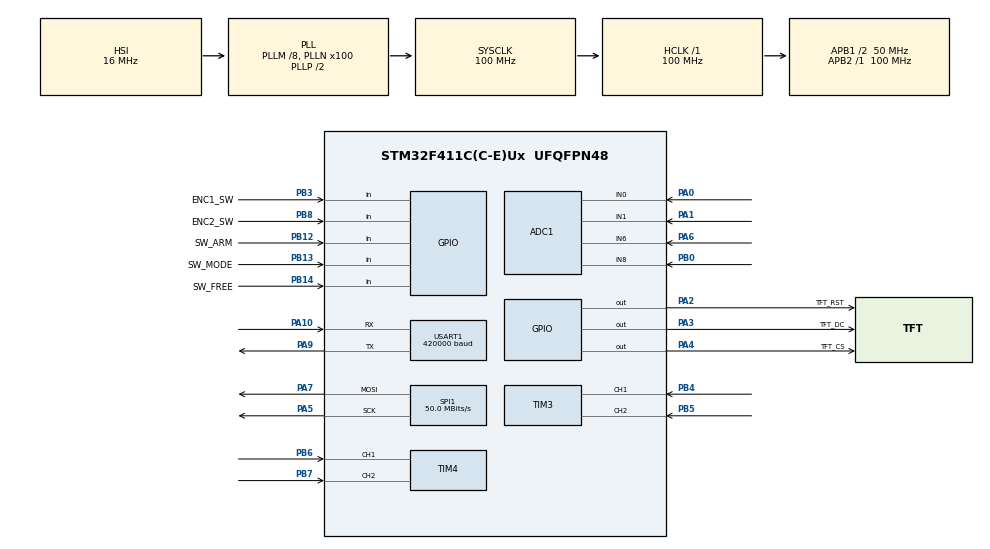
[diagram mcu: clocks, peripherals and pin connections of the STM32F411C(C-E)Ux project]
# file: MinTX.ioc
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ADC1.Channel-0\#ChannelRegularConversion=ADC_CHANNEL_0
ADC1.Channel-1\#ChannelRegularConversion=ADC_CHANNEL_1
ADC1.Channel-2\#ChannelRegularConversion=ADC_CHANNEL_6
ADC1.Channel-3\#ChannelRegularConversion=ADC_CHANNEL_8
ADC1.ContinuousConvMode=ENABLE
ADC1.DMAContinuousRequests=ENABLE
ADC1.EOCSelection=ADC_EOC_SEQ_CONV
ADC1.NbrOfConversion=4
ADC1.NbrOfConversionFlag=1
ADC1.Rank-0\#ChannelRegularConversion=1
ADC1.Rank-1\#ChannelRegularConversion=2
ADC1.Rank-2\#ChannelRegularConversion=3
ADC1.Rank-3\#ChannelRegularConversion=4
ADC1.SamplingTime-0\#ChannelRegularConversion=ADC_SAMPLETIME_84CYCLES
ADC1.SamplingTime-1\#ChannelRegularConversion=ADC_SAMPLETIME_84CYCLES
ADC1.SamplingTime-2\#ChannelRegularConversion=ADC_SAMPLETIME_84CYCLES
ADC1.SamplingTime-3\#ChannelRegularConversion=ADC_SAMPLETIME_84CYCLES
ADC1.ScanConvMode=ENABLE
ADC1.master=1
Dma.ADC1.0.Direction=DMA_PERIPH_TO_MEMORY
Dma.ADC1.0.FIFOMode=DMA_FIFOMODE_DISABLE
Dma.ADC1.0.Instance=DMA2_Stream0
Dma.ADC1.0.MemDataAlignment=DMA_MDATAALIGN_HALFWORD
Dma.ADC1.0.MemInc=DMA_MINC_ENABLE
Dma.ADC1.0.Mode=DMA_CIRCULAR
Dma.ADC1.0.PeriphDataAlignment=DMA_PDATAALIGN_HALFWORD
Dma.ADC1.0.PeriphInc=DMA_PINC_DISABLE
Dma.ADC1.0.Priority=DMA_PRIORITY_LOW
Dma.Request0=ADC1
Dma.Request1=SPI1_TX
Dma.SPI1_TX.1.Direction=DMA_MEMORY_TO_PERIPH
Dma.SPI1_TX.1.FIFOMode=DMA_FIFOMODE_DISABLE
Dma.SPI1_TX.1.Instance=DMA2_Stream2
Dma.SPI1_TX.1.MemDataAlignment=DMA_MDATAALIGN_BYTE
Dma.SPI1_TX.1.MemInc=DMA_MINC_ENABLE
Dma.SPI1_TX.1.Mode=DMA_NORMAL
Dma.SPI1_TX.1.PeriphDataAlignment=DMA_PDATAALIGN_BYTE
Dma.SPI1_TX.1.PeriphInc=DMA_PINC_DISABLE
Dma.SPI1_TX.1.Priority=DMA_PRIORITY_LOW
FREERTOS.Queues01=rcDataQueue,4,uint16_t,0,Dynamic,NULL,NULL
FREERTOS.Tasks01=DisplayTask,24,512,StartDisplayTask,Default,NULL,Dynamic,NULL,NULL;InputTask,40,256,StartInputTask,Default,NULL,Dynamic,NULL,NULL;CrsfTask,48,256,StartCrsfTask,Default,NULL,Dynamic,NULL,NULL;TelemetryTask,8,128,StartMonitorTask,Default,NULL,Dynamic,NULL,NULL
FREERTOS.configTOTAL_HEAP_SIZE=20480
Mcu.Family=STM32F4
Mcu.Name=STM32F411C(C-E)Ux
Mcu.Package=UFQFPN48
NVIC.DMA2_Stream0_IRQn=true\:5\:0\:false\:false\:true\:true\:false\:true\:true
NVIC.DMA2_Stream2_IRQn=true\:5\:0\:false\:false\:true\:true\:false\:true\:true
NVIC.PriorityGroup=NVIC_PRIORITYGROUP_4
NVIC.TIM1_TRG_COM_TIM11_IRQn=true\:15\:0\:false\:false\:true\:false\:false\:true\:true
NVIC.TimeBase=TIM1_TRG_COM_TIM11_IRQn
NVIC.TimeBaseIP=TIM11
NVIC.USART1_IRQn=true\:5\:0\:false\:false\:true\:true\:true\:true\:true
PA0-WKUP.Signal=ADCx_IN0
PA1.Signal=ADCx_IN1
PA10.Mode=Asynchronous
PA10.Signal=USART1_RX
PA13.Mode=Serial_Wire
PA13.Signal=SYS_JTMS-SWDIO
PA14.Mode=Serial_Wire
PA14.Signal=SYS_JTCK-SWCLK
PA2.GPIO_Label=TFT_RST
PA2.GPIO_Speed=GPIO_SPEED_FREQ_HIGH
PA2.PinState=GPIO_PIN_SET
PA2.Signal=GPIO_Output
PA3.GPIO_Label=TFT_DC
PA3.GPIO_Speed=GPIO_SPEED_FREQ_HIGH
PA3.PinState=GPIO_PIN_SET
PA3.Signal=GPIO_Output
PA4.GPIO_Label=TFT_CS
PA4.GPIO_Speed=GPIO_SPEED_FREQ_HIGH
PA4.PinState=GPIO_PIN_SET
PA4.Signal=GPIO_Output
PA5.Mode=TX_Only_Simplex_Unidirect_Master
PA5.Signal=SPI1_SCK
PA6.Signal=ADCx_IN6
PA7.Mode=TX_Only_Simplex_Unidirect_Master
PA7.Signal=SPI1_MOSI
PA9.Mode=Asynchronous
PA9.Signal=USART1_TX
PB0.Signal=ADCx_IN8
PB12.GPIO_Label=SW_ARM
PB12.GPIO_PuPd=GPIO_PULLUP
PB12.Signal=GPIO_Input
PB13.GPIO_Label=SW_MODE
PB13.GPIO_PuPd=GPIO_PULLUP
PB13.Signal=GPIO_Input
PB14.GPIO_Label=SW_FREE
PB14.GPIO_PuPd=GPIO_PULLUP
PB14.Signal=GPIO_Input
PB3.GPIO_Label=ENC1_SW
PB3.GPIO_PuPd=GPIO_PULLUP
PB3.Signal=GPIO_Input
PB4.GPIO_PuPd=GPIO_PULLUP
PB4.Signal=S_TIM3_CH1
PB5.GPIO_PuPd=GPIO_PULLUP
PB5.Signal=S_TIM3_CH2
PB6.GPIO_PuPd=GPIO_PULLUP
PB6.Signal=S_TIM4_CH1
PB7.GPIO_PuPd=GPIO_PULLUP
PB7.Signal=S_TIM4_CH2
PB8.GPIO_Label=ENC2_SW
PB8.GPIO_PuPd=GPIO_PULLUP
PB8.Signal=GPIO_Input
PH0\ -\ OSC_IN.Mode=HSE-External-Oscillator
PH0\ -\ OSC_IN.Signal=RCC_OSC_IN
PH1\ -\ OSC_OUT.Mode=HSE-External-Oscillator
PH1\ -\ OSC_OUT.Signal=RCC_OSC_OUT
ProjectManager.HeapSize=0x200
ProjectManager.StackSize=0x400
ProjectManager.TargetToolchain=STM32CubeIDE
RCC.48MHZClocksFreq_Value=50000000
RCC.AHBFreq_Value=100000000
RCC.APB1CLKDivider=RCC_HCLK_DIV2
RCC.APB1Freq_Value=50000000
RCC.APB1TimFreq_Value=100000000
RCC.APB2Freq_Value=100000000
RCC.APB2TimFreq_Value=100000000
RCC.CortexFreq_Value=100000000
RCC.HCLKFreq_Value=100000000
RCC.HSE_VALUE=25000000
RCC.HSI_VALUE=16000000
RCC.LSE_VALUE=32768
RCC.PLLM=8
RCC.PLLN=100
RCC.SYSCLKFreq_VALUE=100000000
RCC.SYSCLKSource=RCC_SYSCLKSOURCE_PLLCLK
RCC.VCOOutputFreq_Value=200000000
SH.ADCx_IN0.0=ADC1_IN0,IN0
SH.ADCx_IN1.0=ADC1_IN1,IN1
SH.ADCx_IN6.0=ADC1_IN6,IN6
SH.ADCx_IN8.0=ADC1_IN8,IN8
SH.S_TIM3_CH1.0=TIM3_CH1,Encoder_Interface
SH.S_TIM3_CH2.0=TIM3_CH2,Encoder_Interface
SH.S_TIM4_CH1.0=TIM4_CH1,Encoder_Interface
SH.S_TIM4_CH2.0=TIM4_CH2,Encoder_Interface
SPI1.CalculateBaudRate=50.0 MBits/s
SPI1.Direction=SPI_DIRECTION_2LINES
SPI1.Mode=SPI_MODE_MASTER
SPI1.VirtualType=VM_MASTER
TIM3.EncoderMode=TIM_ENCODERMODE_TI12
TIM4.EncoderMode=TIM_ENCODERMODE_TI12
USART1.BaudRate=420000
USART1.VirtualMode=VM_ASYNC
VP_FREERTOS_VS_CMSIS_V2.Mode=CMSIS_V2
VP_SYS_VS_tim11.Mode=TIM11
board=custom

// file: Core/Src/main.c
/* USER CODE BEGIN Header */
/**
  ******************************************************************************
  * @file           : main.c
  * @brief          : Main program body
  ******************************************************************************
  * @attention
  *
  * Copyright (c) 2026 STMicroelectronics.
  * All rights reserved.
  *
  * This software is licensed under terms that can be found in the LICENSE file
  * in the root directory of this software component.
  * If no LICENSE file comes with this software, it is provided AS-IS.
  *
  ******************************************************************************
  */
/* USER CODE END Header */
#include "main.h"
#include "cmsis_os.h"
#include "adc.h"
#include "dma.h"
#include "spi.h"
#include "tim.h"
#include "usart.h"
#include "gpio.h"

void SystemClock_Config(void);
void MX_FREERTOS_Init(void);

int main(void)
{

  /* MCU Configuration--------------------------------------------------------*/

  /* Reset of all peripherals, Initializes the Flash interface and the Systick. */
  HAL_Init();

  /* Configure the system clock */
  SystemClock_Config();

  /* Initialize all configured peripherals */
  MX_GPIO_Init();
  MX_DMA_Init();
  MX_SPI1_Init();
  MX_ADC1_Init();
  MX_TIM3_Init();
  MX_TIM4_Init();
  MX_USART1_UART_Init();

  /* Init scheduler */
  osKernelInitialize();  /* Call init function for freertos objects (in cmsis_os2.c) */
  MX_FREERTOS_Init();

  /* Start scheduler */
  osKernelStart();

  /* We should never get here as control is now taken by the scheduler */

  /* Infinite loop */
  while (1)
  {

  }
}

void SystemClock_Config(void)
{
  RCC_OscInitTypeDef RCC_OscInitStruct = {0};
  RCC_ClkInitTypeDef RCC_ClkInitStruct = {0};

  /** Configure the main internal regulator output voltage
  */
  __HAL_RCC_PWR_CLK_ENABLE();
  __HAL_PWR_VOLTAGESCALING_CONFIG(PWR_REGULATOR_VOLTAGE_SCALE1);

  /** Initializes the RCC Oscillators according to the specified parameters
  * in the RCC_OscInitTypeDef structure.
  */
  RCC_OscInitStruct.OscillatorType = RCC_OSCILLATORTYPE_HSI;
  RCC_OscInitStruct.HSIState = RCC_HSI_ON;
  RCC_OscInitStruct.HSICalibrationValue = RCC_HSICALIBRATION_DEFAULT;
  RCC_OscInitStruct.PLL.PLLState = RCC_PLL_ON;
  RCC_OscInitStruct.PLL.PLLSource = RCC_PLLSOURCE_HSI;
  RCC_OscInitStruct.PLL.PLLM = 8;
  RCC_OscInitStruct.PLL.PLLN = 100;
  RCC_OscInitStruct.PLL.PLLP = RCC_PLLP_DIV2;
  RCC_OscInitStruct.PLL.PLLQ = 4;
  if (HAL_RCC_OscConfig(&RCC_OscInitStruct) != HAL_OK)
  {
    Error_Handler();
  }

  /** Initializes the CPU, AHB and APB buses clocks
  */
  RCC_ClkInitStruct.ClockType = RCC_CLOCKTYPE_HCLK|RCC_CLOCKTYPE_SYSCLK
                              |RCC_CLOCKTYPE_PCLK1|RCC_CLOCKTYPE_PCLK2;
  RCC_ClkInitStruct.SYSCLKSource = RCC_SYSCLKSOURCE_PLLCLK;
  RCC_ClkInitStruct.AHBCLKDivider = RCC_SYSCLK_DIV1;
  RCC_ClkInitStruct.APB1CLKDivider = RCC_HCLK_DIV2;
  RCC_ClkInitStruct.APB2CLKDivider = RCC_HCLK_DIV1;

  if (HAL_RCC_ClockConfig(&RCC_ClkInitStruct, FLASH_LATENCY_3) != HAL_OK)
  {
    Error_Handler();
  }
}

void HAL_TIM_PeriodElapsedCallback(TIM_HandleTypeDef *htim)
{
  if (htim->Instance == TIM11)
  {
    HAL_IncTick();
  }
}

void Error_Handler(void)
{
  __disable_irq();
  while (1)
  {
  }
}

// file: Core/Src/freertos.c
/* USER CODE BEGIN Header */
/**
  ******************************************************************************
  * File Name          : freertos.c
  * Description        : Code for freertos applications
  ******************************************************************************
  * @attention
  *
  * Copyright (c) 2026 STMicroelectronics.
  * All rights reserved.
  *
  * This software is licensed under terms that can be found in the LICENSE file
  * in the root directory of this software component.
  * If no LICENSE file comes with this software, it is provided AS-IS.
  *
  ******************************************************************************
  */
/* USER CODE END Header */

#include "FreeRTOS.h"
#include "task.h"
#include "main.h"
#include "cmsis_os.h"

/* USER CODE BEGIN Includes */
#include "app_main.h"
/* USER CODE END Includes */

/* Definitions for DisplayTask */
osThreadId_t DisplayTaskHandle;
const osThreadAttr_t DisplayTask_attributes = {
  .name = "DisplayTask",
  .stack_size = 512 * 4,
  .priority = (osPriority_t) osPriorityNormal,
};
/* Definitions for InputTask */
osThreadId_t InputTaskHandle;
const osThreadAttr_t InputTask_attributes = {
  .name = "InputTask",
  .stack_size = 256 * 4,
  .priority = (osPriority_t) osPriorityHigh,
};
/* Definitions for CrsfTask */
osThreadId_t CrsfTaskHandle;
const osThreadAttr_t CrsfTask_attributes = {
  .name = "CrsfTask",
  .stack_size = 256 * 4,
  .priority = (osPriority_t) osPriorityRealtime,
};
/* Definitions for TelemetryTask */
osThreadId_t TelemetryTaskHandle;
const osThreadAttr_t TelemetryTask_attributes = {
  .name = "TelemetryTask",
  .stack_size = 128 * 4,
  .priority = (osPriority_t) osPriorityLow,
};
/* Definitions for rcDataQueue */
osMessageQueueId_t rcDataQueueHandle;
const osMessageQueueAttr_t rcDataQueue_attributes = {
  .name = "rcDataQueue"
};

void StartDisplayTask(void *argument);
void StartInputTask(void *argument);
void StartCrsfTask(void *argument);
void StartMonitorTask(void *argument);

void MX_FREERTOS_Init(void); /* (MISRA C 2004 rule 8.1) */

void MX_FREERTOS_Init(void) {

  /* Create the queue(s) */
  /* creation of rcDataQueue */
  rcDataQueueHandle = osMessageQueueNew (4, sizeof(uint16_t), &rcDataQueue_attributes);

  /* Create the thread(s) */
  /* creation of DisplayTask */
  DisplayTaskHandle = osThreadNew(StartDisplayTask, NULL, &DisplayTask_attributes);

  /* creation of InputTask */
  InputTaskHandle = osThreadNew(StartInputTask, NULL, &InputTask_attributes);

  /* creation of CrsfTask */
  CrsfTaskHandle = osThreadNew(StartCrsfTask, NULL, &CrsfTask_attributes);

  /* creation of TelemetryTask */
  TelemetryTaskHandle = osThreadNew(StartMonitorTask, NULL, &TelemetryTask_attributes);

}

void StartDisplayTask(void *argument)
{
  /* USER CODE BEGIN StartDisplayTask */
  /* Infinite loop */
  for(;;)
  {
	App_DisplayTask(argument);
    osDelay(1);
  }
  /* USER CODE END StartDisplayTask */
}

void StartInputTask(void *argument)
{
  /* USER CODE BEGIN StartInputTask */
  /* Infinite loop */
  for(;;)
  {
	App_InputTask(argument);
    osDelay(1);
  }
  /* USER CODE END StartInputTask */
}

void StartCrsfTask(void *argument)
{
  /* USER CODE BEGIN StartCrsfTask */
  /* Infinite loop */
  for(;;)
  {
	App_CrsfTask(argument);
    osDelay(1);
  }
  /* USER CODE END StartCrsfTask */
}

void StartMonitorTask(void *argument)
{
  for(;;)
  {
    osDelay(1);
  }
}
